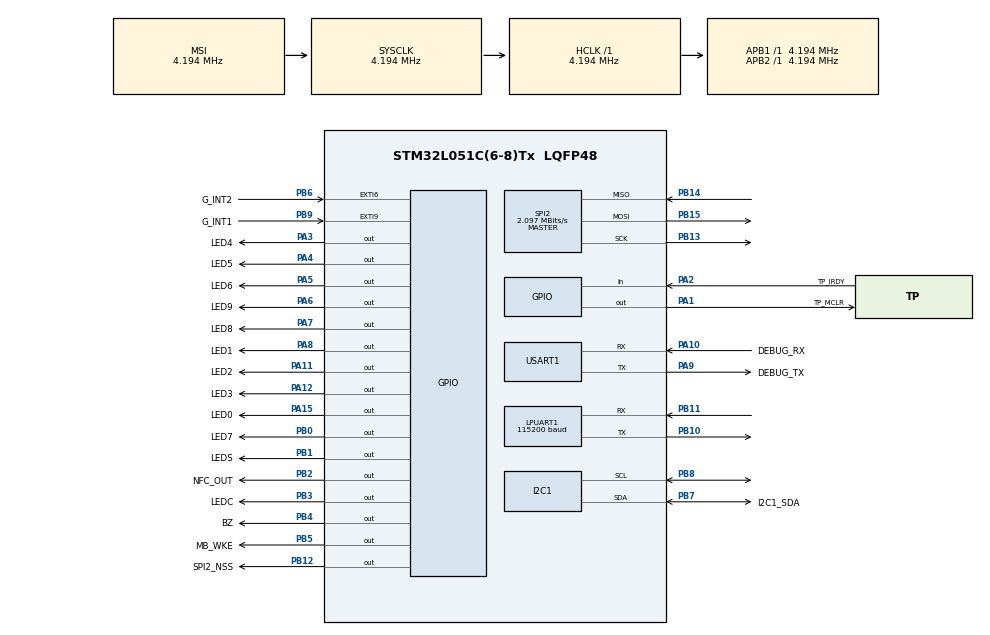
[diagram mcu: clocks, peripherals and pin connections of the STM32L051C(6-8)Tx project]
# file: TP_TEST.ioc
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I2C1.Timing=0x00100E16
LPUART1.BaudRate=115200
LPUART1.WordLength=UART_WORDLENGTH_8B
Mcu.Family=STM32L0
Mcu.Name=STM32L051C(6-8)Tx
Mcu.Package=LQFP48
NVIC.AES_RNG_LPUART1_IRQn=true\:0\:0\:false\:false\:true
NVIC.EXTI4_15_IRQn=true\:0\:0\:false\:false\:true
PA0.Mode=SYS_WakeUp0
PA0.Signal=SYS_WKUP1
PA1.GPIO_Label=TP_MCLR
PA1.Signal=GPIO_Output
PA10.GPIO_Label=DEBUG_RX
PA10.Mode=Asynchronous
PA10.Signal=USART1_RX
PA11.GPIO_Label=LED2
PA11.Signal=GPIO_Output
PA12.GPIO_Label=LED3
PA12.Signal=GPIO_Output
PA13.Mode=Serial_Wire
PA13.Signal=SYS_SWDIO
PA14.Mode=Serial_Wire
PA14.Signal=SYS_SWCLK
PA15.GPIO_Label=LED0
PA15.Signal=GPIO_Output
PA2.GPIO_Label=TP_IRDY
PA2.Signal=GPIO_Input
PA3.GPIO_Label=LED4
PA3.Signal=GPIO_Output
PA4.GPIO_Label=LED5
PA4.Signal=GPIO_Output
PA5.GPIO_Label=LED6
PA5.Signal=GPIO_Output
PA6.GPIO_Label=LED9
PA6.Signal=GPIO_Output
PA7.GPIO_Label=LED8
PA7.Signal=GPIO_Output
PA8.GPIO_Label=LED1
PA8.Signal=GPIO_Output
PA9.GPIO_Label=DEBUG_TX
PA9.Mode=Asynchronous
PA9.Signal=USART1_TX
PB0.GPIO_Label=LED7
PB0.Signal=GPIO_Output
PB1.GPIO_Label=LEDS
PB1.Signal=GPIO_Output
PB10.Mode=Asynchronous
PB10.Signal=LPUART1_TX
PB11.Mode=Asynchronous
PB11.Signal=LPUART1_RX
PB12.GPIO_Label=SPI2_NSS
PB12.Signal=GPIO_Output
PB13.Mode=Full_Duplex_Master
PB13.Signal=SPI2_SCK
PB14.Mode=Full_Duplex_Master
PB14.Signal=SPI2_MISO
PB15.Mode=Full_Duplex_Master
PB15.Signal=SPI2_MOSI
PB2.GPIO_Label=NFC_OUT
PB2.Signal=GPIO_Output
PB3.GPIO_Label=LEDC
PB3.Signal=GPIO_Output
PB4.GPIO_Label=BZ
PB4.Signal=GPIO_Output
PB5.GPIO_Label=MB_WKE
PB5.Signal=GPIO_Output
PB6.GPIO_Label=G_INT2
PB6.Signal=GPXTI6
PB7.GPIO_Label=I2C1_SDA
PB7.Mode=I2C
PB7.Signal=I2C1_SDA
PB8.Mode=I2C
PB8.Signal=I2C1_SCL
PB9.GPIO_Label=G_INT1
PB9.Signal=GPXTI9
ProjectManager.HeapSize=0x200
ProjectManager.StackSize=0x400
ProjectManager.TargetToolchain=MDK-ARM V5
RCC.AHBFreq_Value=4194000
RCC.APB1Freq_Value=4194000
RCC.APB1TimFreq_Value=4194000
RCC.APB2Freq_Value=4194000
RCC.APB2TimFreq_Value=4194000
RCC.HCLKFreq_Value=4194000
RCC.HSE_VALUE=8000000
RCC.HSI16_VALUE=16000000
RCC.HSI_VALUE=16000000
RCC.I2c1ClockSelection=RCC_I2C1CLKSOURCE_SYSCLK
RCC.LSE_VALUE=32768
RCC.Lpuart1ClockSelection=RCC_LPUART1CLKSOURCE_SYSCLK
RCC.MSIClockRange=RCC_MSIRANGE_6
RCC.MSI_VALUE=4194000
RCC.SYSCLKFreq_VALUE=4194000
RCC.Usart1ClockSelection=RCC_USART1CLKSOURCE_SYSCLK
RCC.VCOOutputFreq_Value=48000000
SPI2.CalculateBaudRate=2.097 MBits/s
SPI2.Direction=SPI_DIRECTION_2LINES
SPI2.Mode=SPI_MODE_MASTER
SPI2.VirtualType=VM_MASTER
USART1.VirtualMode-Asynchronous=VM_ASYNC
USART1.WordLength=WORDLENGTH_8B
board=TP_TEST

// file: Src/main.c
/**
  ******************************************************************************
  * File Name          : main.c
  * Description        : Main program body
  ******************************************************************************
  ** This notice applies to any and all portions of this file
  * that are not between comment pairs USER CODE BEGIN and
  * USER CODE END. Other portions of this file, whether
  * inserted by the user or by software development tools
  * are owned by their respective copyright owners.
  *
  * COPYRIGHT(c) 2017 STMicroelectronics
  *
  * Redistribution and use in source and binary forms, with or without modification,
  * are permitted provided that the following conditions are met:
  *   1. Redistributions of source code must retain the above copyright notice,
  *      this list of conditions and the following disclaimer.
  *   2. Redistributions in binary form must reproduce the above copyright notice,
  *      this list of conditions and the following disclaimer in the documentation
  *      and/or other materials provided with the distribution.
  *   3. Neither the name of STMicroelectronics nor the names of its contributors
  *      may be used to endorse or promote products derived from this software
  *      without specific prior written permission.
  *
  * THIS SOFTWARE IS PROVIDED BY THE COPYRIGHT HOLDERS AND CONTRIBUTORS "AS IS"
  * AND ANY EXPRESS OR IMPLIED WARRANTIES, INCLUDING, BUT NOT LIMITED TO, THE
  * IMPLIED WARRANTIES OF MERCHANTABILITY AND FITNESS FOR A PARTICULAR PURPOSE ARE
  * DISCLAIMED. IN NO EVENT SHALL THE COPYRIGHT HOLDER OR CONTRIBUTORS BE LIABLE
  * FOR ANY DIRECT, INDIRECT, INCIDENTAL, SPECIAL, EXEMPLARY, OR CONSEQUENTIAL
  * DAMAGES (INCLUDING, BUT NOT LIMITED TO, PROCUREMENT OF SUBSTITUTE GOODS OR
  * SERVICES; LOSS OF USE, DATA, OR PROFITS; OR BUSINESS INTERRUPTION) HOWEVER
  * CAUSED AND ON ANY THEORY OF LIABILITY, WHETHER IN CONTRACT, STRICT LIABILITY,
  * OR TORT (INCLUDING NEGLIGENCE OR OTHERWISE) ARISING IN ANY WAY OUT OF THE USE
  * OF THIS SOFTWARE, EVEN IF ADVISED OF THE POSSIBILITY OF SUCH DAMAGE.
  *
  ******************************************************************************
  */
#include "main.h"
#include "stm32l0xx_hal.h"
#include "iqs316_driver.h"

/* USER CODE BEGIN Includes */
#ifdef __GNUC__
  /* With GCC/RAISONANCE, small printf (option LD Linker->Libraries->Small printf
     set to 'Yes') calls __io_putchar() */
  #define PUTCHAR_PROTOTYPE int __io_putchar(int ch)
#else
  #define PUTCHAR_PROTOTYPE int fputc(int ch, FILE *f)
#endif /* __GNUC__ */
/* USER CODE END Includes */

I2C_HandleTypeDef hi2c1;

UART_HandleTypeDef hlpuart1;
UART_HandleTypeDef huart1;

SPI_HandleTypeDef hspi2;

/* USER CODE BEGIN PV */
/* Private variables ---------------------------------------------------------*/

/* USER CODE END PV */

void SystemClock_Config(void);
static void MX_GPIO_Init(void);
static void MX_I2C1_Init(void);
static void MX_LPUART1_UART_Init(void);
static void MX_SPI2_Init(void);
static void MX_USART1_UART_Init(void);

/* USER CODE BEGIN PFP */
/* Private function prototypes -----------------------------------------------*/

/* USER CODE END PFP */

int main(void)
{

  /* MCU Configuration----------------------------------------------------------*/

  /* Reset of all peripherals, Initializes the Flash interface and the Systick. */
  HAL_Init();

  /* Configure the system clock */
  SystemClock_Config();

  /* Initialize all configured peripherals */
  MX_GPIO_Init();
  MX_I2C1_Init();
  MX_LPUART1_UART_Init();
  MX_SPI2_Init();
  MX_USART1_UART_Init();

  /* USER CODE BEGIN 2 */
  printf("IQS316 test\r\n");
  BZ_On();
  HAL_Delay(300);
  BZ_Off();
  IQS316_Init();
  /* USER CODE END 2 */

  /* Infinite loop */
  while (1)
  {
    LED_Toggle(LED5);
    HAL_Delay(100);
    //
    // Get data from latest comms window
    //
    IQS316_Refresh_Data();
    //
    // Process this new data accordingly
    //
    IQS316_Process_Data();
  }

}

/** System Clock Configuration
*/
void SystemClock_Config(void)
{

  RCC_OscInitTypeDef RCC_OscInitStruct;
  RCC_ClkInitTypeDef RCC_ClkInitStruct;
  RCC_PeriphCLKInitTypeDef PeriphClkInit;

    /**Configure the main internal regulator output voltage
    */
  __HAL_PWR_VOLTAGESCALING_CONFIG(PWR_REGULATOR_VOLTAGE_SCALE1);

    /**Initializes the CPU, AHB and APB busses clocks
    */
  RCC_OscInitStruct.OscillatorType = RCC_OSCILLATORTYPE_MSI;
  RCC_OscInitStruct.MSIState = RCC_MSI_ON;
  RCC_OscInitStruct.MSICalibrationValue = 0;
  RCC_OscInitStruct.MSIClockRange = RCC_MSIRANGE_6;
  RCC_OscInitStruct.PLL.PLLState = RCC_PLL_NONE;
  if (HAL_RCC_OscConfig(&RCC_OscInitStruct) != HAL_OK)
  {
    _Error_Handler(__FILE__, __LINE__);
  }

    /**Initializes the CPU, AHB and APB busses clocks
    */
  RCC_ClkInitStruct.ClockType = RCC_CLOCKTYPE_HCLK|RCC_CLOCKTYPE_SYSCLK
                              |RCC_CLOCKTYPE_PCLK1|RCC_CLOCKTYPE_PCLK2;
  RCC_ClkInitStruct.SYSCLKSource = RCC_SYSCLKSOURCE_MSI;
  RCC_ClkInitStruct.AHBCLKDivider = RCC_SYSCLK_DIV1;
  RCC_ClkInitStruct.APB1CLKDivider = RCC_HCLK_DIV1;
  RCC_ClkInitStruct.APB2CLKDivider = RCC_HCLK_DIV1;

  if (HAL_RCC_ClockConfig(&RCC_ClkInitStruct, FLASH_LATENCY_0) != HAL_OK)
  {
    _Error_Handler(__FILE__, __LINE__);
  }

  PeriphClkInit.PeriphClockSelection = RCC_PERIPHCLK_USART1|RCC_PERIPHCLK_LPUART1
                              |RCC_PERIPHCLK_I2C1;
  PeriphClkInit.Usart1ClockSelection = RCC_USART1CLKSOURCE_SYSCLK;
  PeriphClkInit.Lpuart1ClockSelection = RCC_LPUART1CLKSOURCE_SYSCLK;
  PeriphClkInit.I2c1ClockSelection = RCC_I2C1CLKSOURCE_SYSCLK;
  if (HAL_RCCEx_PeriphCLKConfig(&PeriphClkInit) != HAL_OK)
  {
    _Error_Handler(__FILE__, __LINE__);
  }

    /**Configure the Systick interrupt time
    */
  HAL_SYSTICK_Config(HAL_RCC_GetHCLKFreq()/1000);

    /**Configure the Systick
    */
  HAL_SYSTICK_CLKSourceConfig(SYSTICK_CLKSOURCE_HCLK);

  /* SysTick_IRQn interrupt configuration */
  HAL_NVIC_SetPriority(SysTick_IRQn, 0, 0);
}

/* I2C1 init function */
static void MX_I2C1_Init(void)
{

  hi2c1.Instance = I2C1;
  hi2c1.Init.Timing = 0x00100E16;
  hi2c1.Init.OwnAddress1 = 0;
  hi2c1.Init.AddressingMode = I2C_ADDRESSINGMODE_7BIT;
  hi2c1.Init.DualAddressMode = I2C_DUALADDRESS_DISABLE;
  hi2c1.Init.OwnAddress2 = 0;
  hi2c1.Init.OwnAddress2Masks = I2C_OA2_NOMASK;
  hi2c1.Init.GeneralCallMode = I2C_GENERALCALL_DISABLE;
  hi2c1.Init.NoStretchMode = I2C_NOSTRETCH_DISABLE;
  if (HAL_I2C_Init(&hi2c1) != HAL_OK)
  {
    _Error_Handler(__FILE__, __LINE__);
  }

    /**Configure Analogue filter
    */
  if (HAL_I2CEx_ConfigAnalogFilter(&hi2c1, I2C_ANALOGFILTER_ENABLE) != HAL_OK)
  {
    _Error_Handler(__FILE__, __LINE__);
  }

    /**Configure Digital filter
    */
  if (HAL_I2CEx_ConfigDigitalFilter(&hi2c1, 0) != HAL_OK)
  {
    _Error_Handler(__FILE__, __LINE__);
  }

}

/* LPUART1 init function */
static void MX_LPUART1_UART_Init(void)
{

  hlpuart1.Instance = LPUART1;
  hlpuart1.Init.BaudRate = 115200;
  hlpuart1.Init.WordLength = UART_WORDLENGTH_8B;
  hlpuart1.Init.StopBits = UART_STOPBITS_1;
  hlpuart1.Init.Parity = UART_PARITY_NONE;
  hlpuart1.Init.Mode = UART_MODE_TX_RX;
  hlpuart1.Init.HwFlowCtl = UART_HWCONTROL_NONE;
  hlpuart1.Init.OneBitSampling = UART_ONE_BIT_SAMPLE_DISABLE;
  hlpuart1.AdvancedInit.AdvFeatureInit = UART_ADVFEATURE_NO_INIT;
  if (HAL_UART_Init(&hlpuart1) != HAL_OK)
  {
    _Error_Handler(__FILE__, __LINE__);
  }

}

/* USART1 init function */
static void MX_USART1_UART_Init(void)
{

  huart1.Instance = USART1;
  huart1.Init.BaudRate = 115200;
  huart1.Init.WordLength = UART_WORDLENGTH_8B;
  huart1.Init.StopBits = UART_STOPBITS_1;
  huart1.Init.Parity = UART_PARITY_NONE;
  huart1.Init.Mode = UART_MODE_TX_RX;
  huart1.Init.HwFlowCtl = UART_HWCONTROL_NONE;
  huart1.Init.OverSampling = UART_OVERSAMPLING_16;
  huart1.Init.OneBitSampling = UART_ONE_BIT_SAMPLE_DISABLE;
  huart1.AdvancedInit.AdvFeatureInit = UART_ADVFEATURE_NO_INIT;
  if (HAL_UART_Init(&huart1) != HAL_OK)
  {
    _Error_Handler(__FILE__, __LINE__);
  }

}

/* SPI2 init function */
static void MX_SPI2_Init(void)
{

  hspi2.Instance = SPI2;
  hspi2.Init.Mode = SPI_MODE_MASTER;
  hspi2.Init.Direction = SPI_DIRECTION_2LINES;
  hspi2.Init.DataSize = SPI_DATASIZE_8BIT;
  hspi2.Init.CLKPolarity = SPI_POLARITY_LOW;
  hspi2.Init.CLKPhase = SPI_PHASE_1EDGE;
  hspi2.Init.NSS = SPI_NSS_SOFT;
  hspi2.Init.BaudRatePrescaler = SPI_BAUDRATEPRESCALER_2;
  hspi2.Init.FirstBit = SPI_FIRSTBIT_MSB;
  hspi2.Init.TIMode = SPI_TIMODE_DISABLE;
  hspi2.Init.CRCCalculation = SPI_CRCCALCULATION_DISABLE;
  hspi2.Init.CRCPolynomial = 7;
  if (HAL_SPI_Init(&hspi2) != HAL_OK)
  {
    _Error_Handler(__FILE__, __LINE__);
  }

}

/** Configure pins as
        * Analog
        * Input
        * Output
        * EVENT_OUT
        * EXTI
*/
static void MX_GPIO_Init(void)
{

  GPIO_InitTypeDef GPIO_InitStruct;

  /* GPIO Ports Clock Enable */
  __HAL_RCC_GPIOA_CLK_ENABLE();
  __HAL_RCC_GPIOB_CLK_ENABLE();

  /*Configure GPIO pin Output Level */
  HAL_GPIO_WritePin(GPIOA, TP_MCLR_Pin|LED4_Pin|LED5_Pin|LED6_Pin
                          |LED9_Pin|LED8_Pin|LED1_Pin|LED2_Pin
                          |LED3_Pin|LED0_Pin, GPIO_PIN_RESET);

  /*Configure GPIO pin Output Level */
  HAL_GPIO_WritePin(GPIOB, LED7_Pin|LEDS_Pin|NFC_OUT_Pin|SPI2_NSS_Pin
                          |LEDC_Pin|BZ_Pin|MB_WKE_Pin, GPIO_PIN_RESET);

  /*Configure GPIO pins : TP_MCLR_Pin LED4_Pin LED5_Pin LED6_Pin
                           LED9_Pin LED8_Pin LED1_Pin LED2_Pin
                           LED3_Pin LED0_Pin */
  GPIO_InitStruct.Pin = TP_MCLR_Pin|LED4_Pin|LED5_Pin|LED6_Pin
                          |LED9_Pin|LED8_Pin|LED1_Pin|LED2_Pin
                          |LED3_Pin|LED0_Pin;
  GPIO_InitStruct.Mode = GPIO_MODE_OUTPUT_PP;
  GPIO_InitStruct.Pull = GPIO_NOPULL;
  GPIO_InitStruct.Speed = GPIO_SPEED_FREQ_LOW;
  HAL_GPIO_Init(GPIOA, &GPIO_InitStruct);

  /*Configure GPIO pin : TP_IRDY_Pin */
  GPIO_InitStruct.Pin = TP_IRDY_Pin;
  GPIO_InitStruct.Mode = GPIO_MODE_INPUT;
  GPIO_InitStruct.Pull = GPIO_NOPULL;
  HAL_GPIO_Init(TP_IRDY_GPIO_Port, &GPIO_InitStruct);

  /*Configure GPIO pins : LED7_Pin LEDS_Pin NFC_OUT_Pin SPI2_NSS_Pin
                           LEDC_Pin BZ_Pin MB_WKE_Pin */
  GPIO_InitStruct.Pin = LED7_Pin|LEDS_Pin|NFC_OUT_Pin|SPI2_NSS_Pin
                          |LEDC_Pin|BZ_Pin|MB_WKE_Pin;
  GPIO_InitStruct.Mode = GPIO_MODE_OUTPUT_PP;
  GPIO_InitStruct.Pull = GPIO_NOPULL;
  GPIO_InitStruct.Speed = GPIO_SPEED_FREQ_LOW;
  HAL_GPIO_Init(GPIOB, &GPIO_InitStruct);

  /*Configure GPIO pins : G_INT2_Pin G_INT1_Pin */
  GPIO_InitStruct.Pin = G_INT2_Pin|G_INT1_Pin;
  GPIO_InitStruct.Mode = GPIO_MODE_IT_RISING;
  GPIO_InitStruct.Pull = GPIO_NOPULL;
  HAL_GPIO_Init(GPIOB, &GPIO_InitStruct);

  /* EXTI interrupt init*/
  HAL_NVIC_SetPriority(EXTI4_15_IRQn, 0, 0);
  HAL_NVIC_EnableIRQ(EXTI4_15_IRQn);

}

void _Error_Handler(char * file, int line)
{
  while(1)
  {
  }
}

/**
  * @brief  Retargets the C library printf function to the USART.
  * @param  None
  * @retval None
  */
PUTCHAR_PROTOTYPE
{
  /* Place your implementation of fputc here */
  /* e.g. write a character to the USART2 and Loop until the end of transmission */
  HAL_UART_Transmit(&huart1, (uint8_t *)&ch, 1, 0xFFFF);

  return ch;
}

/************************ (C) COPYRIGHT STMicroelectronics *****END OF FILE****/
